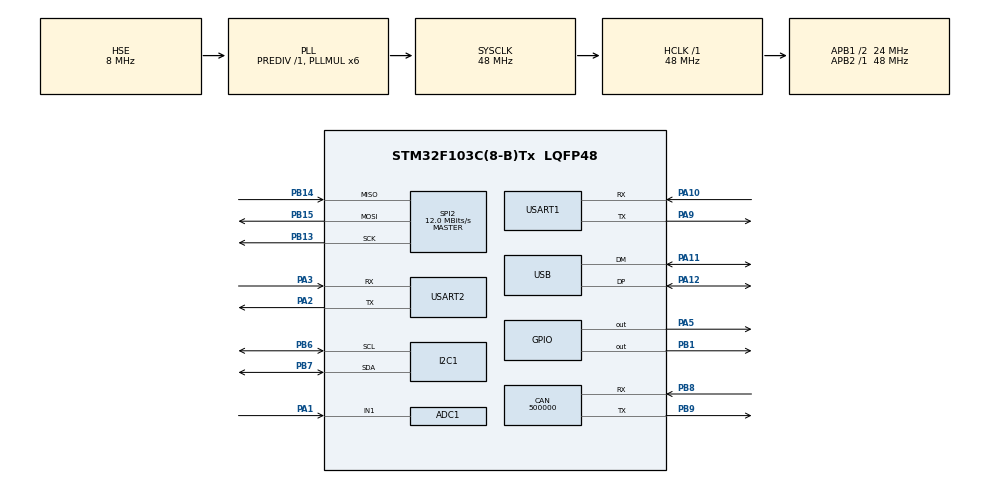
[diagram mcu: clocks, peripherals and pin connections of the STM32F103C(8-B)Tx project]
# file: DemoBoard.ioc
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ADC1.Channel-0\#ChannelRegularConversion=ADC_CHANNEL_1
ADC1.NbrOfConversionFlag=1
ADC1.Rank-0\#ChannelRegularConversion=1
ADC1.SamplingTime-0\#ChannelRegularConversion=ADC_SAMPLETIME_1CYCLE_5
ADC1.master=1
CAN.CalculateBaudRate=500000
CAN.CalculateTimeBit=1999.99
CAN.CalculateTimeQuantum=666.6666666666666
FREERTOS.Tasks01=defaultTask,24,128,StartDefaultTask,Default,NULL,Dynamic,NULL,NULL
Mcu.Family=STM32F1
Mcu.Name=STM32F103C(8-B)Tx
Mcu.Package=LQFP48
NVIC.PriorityGroup=NVIC_PRIORITYGROUP_4
NVIC.USB_LP_CAN1_RX0_IRQn=true\:5\:0\:false\:false\:true\:true\:false\:true
PA1.Signal=ADCx_IN1
PA10.Mode=Asynchronous
PA10.Signal=USART1_RX
PA11.Mode=Device
PA11.Signal=USB_DM
PA12.Mode=Device
PA12.Signal=USB_DP
PA13.Mode=Serial_Wire
PA13.Signal=SYS_JTMS-SWDIO
PA14.Mode=Serial_Wire
PA14.Signal=SYS_JTCK-SWCLK
PA2.Mode=Asynchronous
PA2.Signal=USART2_TX
PA3.Mode=Asynchronous
PA3.Signal=USART2_RX
PA5.Signal=GPIO_Output
PA9.Mode=Asynchronous
PA9.Signal=USART1_TX
PB1.Signal=GPIO_Output
PB13.Mode=Full_Duplex_Master
PB13.Signal=SPI2_SCK
PB14.Mode=Full_Duplex_Master
PB14.Signal=SPI2_MISO
PB15.Mode=Full_Duplex_Master
PB15.Signal=SPI2_MOSI
PB6.Mode=I2C
PB6.Signal=I2C1_SCL
PB7.Mode=I2C
PB7.Signal=I2C1_SDA
PB8.Mode=CAN_Activate
PB8.Signal=CAN_RX
PB9.Mode=CAN_Activate
PB9.Signal=CAN_TX
PD0-OSC_IN.Mode=HSE-External-Oscillator
PD0-OSC_IN.Signal=RCC_OSC_IN
PD1-OSC_OUT.Mode=HSE-External-Oscillator
PD1-OSC_OUT.Signal=RCC_OSC_OUT
ProjectManager.HeapSize=0x200
ProjectManager.StackSize=0x400
ProjectManager.TargetToolchain=STM32CubeIDE
RCC.ADCPresc=RCC_ADCPCLK2_DIV4
RCC.AHBFreq_Value=48000000
RCC.APB1CLKDivider=RCC_HCLK_DIV2
RCC.APB1Freq_Value=24000000
RCC.APB1TimFreq_Value=48000000
RCC.APB2Freq_Value=48000000
RCC.APB2TimFreq_Value=48000000
RCC.HCLKFreq_Value=48000000
RCC.PLLMUL=RCC_PLL_MUL6
RCC.SYSCLKFreq_VALUE=48000000
RCC.SYSCLKSource=RCC_SYSCLKSOURCE_PLLCLK
RCC.USBFreq_Value=48000000
SH.ADCx_IN1.0=ADC1_IN1,IN1
SPI2.CalculateBaudRate=12.0 MBits/s
SPI2.Direction=SPI_DIRECTION_2LINES
SPI2.Mode=SPI_MODE_MASTER
SPI2.VirtualType=VM_MASTER
USART1.VirtualMode=VM_ASYNC
USART2.VirtualMode=VM_ASYNC
USB_DEVICE.CLASS_NAME_FS=CDC
USB_DEVICE.VirtualMode=Cdc
USB_DEVICE.VirtualModeFS=Cdc_FS
VP_FREERTOS_VS_CMSIS_V2.Mode=CMSIS_V2
VP_USB_DEVICE_VS_USB_DEVICE_CDC_FS.Mode=CDC_FS
board=custom

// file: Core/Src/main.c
/* USER CODE BEGIN Header */
/**
  ******************************************************************************
  * @file           : main.c
  * @brief          : Main program body
  ******************************************************************************
  * @attention
  *
  * <h2><center>&copy; Copyright (c) 2021 STMicroelectronics.
  * All rights reserved.</center></h2>
  *
  * This software component is licensed by ST under BSD 3-Clause license,
  * the "License"; You may not use this file except in compliance with the
  * License. You may obtain a copy of the License at:
  *                        opensource.org/licenses/BSD-3-Clause
  *
  ******************************************************************************
  */
/* USER CODE END Header */
#include "main.h"
#include "cmsis_os.h"
#include "usb_device.h"

ADC_HandleTypeDef hadc1;

CAN_HandleTypeDef hcan;

I2C_HandleTypeDef hi2c1;

SPI_HandleTypeDef hspi2;

UART_HandleTypeDef huart1;
UART_HandleTypeDef huart2;

/* Definitions for defaultTask */
osThreadId_t defaultTaskHandle;
const osThreadAttr_t defaultTask_attributes = {
  .name = "defaultTask",
  .priority = (osPriority_t) osPriorityNormal,
  .stack_size = 128 * 4
};

void SystemClock_Config(void);
static void MX_GPIO_Init(void);
static void MX_I2C1_Init(void);
static void MX_USART1_UART_Init(void);
static void MX_USART2_UART_Init(void);
static void MX_ADC1_Init(void);
static void MX_CAN_Init(void);
static void MX_SPI2_Init(void);
void StartDefaultTask(void *argument);

/* USER CODE BEGIN 0 */
#define LED0_Pin        GPIO_PIN_5
#define LED0_GPIO_Port  GPIOA
#define LED_ON          GPIO_PIN_SET
#define LED_OFF          GPIO_PIN_RESET

/* USER CODE END 0 */

int main(void)
{

  /* MCU Configuration--------------------------------------------------------*/

  /* Reset of all peripherals, Initializes the Flash interface and the Systick. */
  HAL_Init();

  /* Configure the system clock */
  SystemClock_Config();

  /* Initialize all configured peripherals */
  MX_GPIO_Init();
  MX_I2C1_Init();
  MX_USART1_UART_Init();
  MX_USART2_UART_Init();
  MX_ADC1_Init();
  MX_CAN_Init();
  MX_SPI2_Init();

  /* Init scheduler */
  osKernelInitialize();

  /* Create the thread(s) */
  /* creation of defaultTask */
  defaultTaskHandle = osThreadNew(StartDefaultTask, NULL, &defaultTask_attributes);

  /* Start scheduler */
  osKernelStart();

  /* We should never get here as control is now taken by the scheduler */
  /* Infinite loop */
  while (1)
  {

  }
}

void SystemClock_Config(void)
{
  RCC_OscInitTypeDef RCC_OscInitStruct = {0};
  RCC_ClkInitTypeDef RCC_ClkInitStruct = {0};
  RCC_PeriphCLKInitTypeDef PeriphClkInit = {0};

  /** Initializes the RCC Oscillators according to the specified parameters
  * in the RCC_OscInitTypeDef structure.
  */
  RCC_OscInitStruct.OscillatorType = RCC_OSCILLATORTYPE_HSE;
  RCC_OscInitStruct.HSEState = RCC_HSE_ON;
  RCC_OscInitStruct.HSEPredivValue = RCC_HSE_PREDIV_DIV1;
  RCC_OscInitStruct.HSIState = RCC_HSI_ON;
  RCC_OscInitStruct.PLL.PLLState = RCC_PLL_ON;
  RCC_OscInitStruct.PLL.PLLSource = RCC_PLLSOURCE_HSE;
  RCC_OscInitStruct.PLL.PLLMUL = RCC_PLL_MUL6;
  if (HAL_RCC_OscConfig(&RCC_OscInitStruct) != HAL_OK)
  {
    Error_Handler();
  }
  /** Initializes the CPU, AHB and APB buses clocks
  */
  RCC_ClkInitStruct.ClockType = RCC_CLOCKTYPE_HCLK|RCC_CLOCKTYPE_SYSCLK
                              |RCC_CLOCKTYPE_PCLK1|RCC_CLOCKTYPE_PCLK2;
  RCC_ClkInitStruct.SYSCLKSource = RCC_SYSCLKSOURCE_PLLCLK;
  RCC_ClkInitStruct.AHBCLKDivider = RCC_SYSCLK_DIV1;
  RCC_ClkInitStruct.APB1CLKDivider = RCC_HCLK_DIV2;
  RCC_ClkInitStruct.APB2CLKDivider = RCC_HCLK_DIV1;

  if (HAL_RCC_ClockConfig(&RCC_ClkInitStruct, FLASH_LATENCY_1) != HAL_OK)
  {
    Error_Handler();
  }
  PeriphClkInit.PeriphClockSelection = RCC_PERIPHCLK_ADC|RCC_PERIPHCLK_USB;
  PeriphClkInit.AdcClockSelection = RCC_ADCPCLK2_DIV4;
  PeriphClkInit.UsbClockSelection = RCC_USBCLKSOURCE_PLL;
  if (HAL_RCCEx_PeriphCLKConfig(&PeriphClkInit) != HAL_OK)
  {
    Error_Handler();
  }
}

static void MX_ADC1_Init(void)
{

  ADC_ChannelConfTypeDef sConfig = {0};

  /** Common config
  */
  hadc1.Instance = ADC1;
  hadc1.Init.ScanConvMode = ADC_SCAN_DISABLE;
  hadc1.Init.ContinuousConvMode = DISABLE;
  hadc1.Init.DiscontinuousConvMode = DISABLE;
  hadc1.Init.ExternalTrigConv = ADC_SOFTWARE_START;
  hadc1.Init.DataAlign = ADC_DATAALIGN_RIGHT;
  hadc1.Init.NbrOfConversion = 1;
  if (HAL_ADC_Init(&hadc1) != HAL_OK)
  {
    Error_Handler();
  }
  /** Configure Regular Channel
  */
  sConfig.Channel = ADC_CHANNEL_1;
  sConfig.Rank = ADC_REGULAR_RANK_1;
  sConfig.SamplingTime = ADC_SAMPLETIME_1CYCLE_5;
  if (HAL_ADC_ConfigChannel(&hadc1, &sConfig) != HAL_OK)
  {
    Error_Handler();
  }

}

static void MX_CAN_Init(void)
{

  hcan.Instance = CAN1;
  hcan.Init.Prescaler = 16;
  hcan.Init.Mode = CAN_MODE_NORMAL;
  hcan.Init.SyncJumpWidth = CAN_SJW_1TQ;
  hcan.Init.TimeSeg1 = CAN_BS1_1TQ;
  hcan.Init.TimeSeg2 = CAN_BS2_1TQ;
  hcan.Init.TimeTriggeredMode = DISABLE;
  hcan.Init.AutoBusOff = DISABLE;
  hcan.Init.AutoWakeUp = DISABLE;
  hcan.Init.AutoRetransmission = DISABLE;
  hcan.Init.ReceiveFifoLocked = DISABLE;
  hcan.Init.TransmitFifoPriority = DISABLE;
  if (HAL_CAN_Init(&hcan) != HAL_OK)
  {
    Error_Handler();
  }

}

static void MX_I2C1_Init(void)
{

  hi2c1.Instance = I2C1;
  hi2c1.Init.ClockSpeed = 100000;
  hi2c1.Init.DutyCycle = I2C_DUTYCYCLE_2;
  hi2c1.Init.OwnAddress1 = 0;
  hi2c1.Init.AddressingMode = I2C_ADDRESSINGMODE_7BIT;
  hi2c1.Init.DualAddressMode = I2C_DUALADDRESS_DISABLE;
  hi2c1.Init.OwnAddress2 = 0;
  hi2c1.Init.GeneralCallMode = I2C_GENERALCALL_DISABLE;
  hi2c1.Init.NoStretchMode = I2C_NOSTRETCH_DISABLE;
  if (HAL_I2C_Init(&hi2c1) != HAL_OK)
  {
    Error_Handler();
  }

}

static void MX_SPI2_Init(void)
{

  /* SPI2 parameter configuration*/
  hspi2.Instance = SPI2;
  hspi2.Init.Mode = SPI_MODE_MASTER;
  hspi2.Init.Direction = SPI_DIRECTION_2LINES;
  hspi2.Init.DataSize = SPI_DATASIZE_8BIT;
  hspi2.Init.CLKPolarity = SPI_POLARITY_LOW;
  hspi2.Init.CLKPhase = SPI_PHASE_1EDGE;
  hspi2.Init.NSS = SPI_NSS_SOFT;
  hspi2.Init.BaudRatePrescaler = SPI_BAUDRATEPRESCALER_2;
  hspi2.Init.FirstBit = SPI_FIRSTBIT_MSB;
  hspi2.Init.TIMode = SPI_TIMODE_DISABLE;
  hspi2.Init.CRCCalculation = SPI_CRCCALCULATION_DISABLE;
  hspi2.Init.CRCPolynomial = 10;
  if (HAL_SPI_Init(&hspi2) != HAL_OK)
  {
    Error_Handler();
  }

}

static void MX_USART1_UART_Init(void)
{

  huart1.Instance = USART1;
  huart1.Init.BaudRate = 115200;
  huart1.Init.WordLength = UART_WORDLENGTH_8B;
  huart1.Init.StopBits = UART_STOPBITS_1;
  huart1.Init.Parity = UART_PARITY_NONE;
  huart1.Init.Mode = UART_MODE_TX_RX;
  huart1.Init.HwFlowCtl = UART_HWCONTROL_NONE;
  huart1.Init.OverSampling = UART_OVERSAMPLING_16;
  if (HAL_UART_Init(&huart1) != HAL_OK)
  {
    Error_Handler();
  }

}

static void MX_USART2_UART_Init(void)
{

  huart2.Instance = USART2;
  huart2.Init.BaudRate = 115200;
  huart2.Init.WordLength = UART_WORDLENGTH_8B;
  huart2.Init.StopBits = UART_STOPBITS_1;
  huart2.Init.Parity = UART_PARITY_NONE;
  huart2.Init.Mode = UART_MODE_TX_RX;
  huart2.Init.HwFlowCtl = UART_HWCONTROL_NONE;
  huart2.Init.OverSampling = UART_OVERSAMPLING_16;
  if (HAL_UART_Init(&huart2) != HAL_OK)
  {
    Error_Handler();
  }

}

static void MX_GPIO_Init(void)
{
  GPIO_InitTypeDef GPIO_InitStruct = {0};

  /* GPIO Ports Clock Enable */
  __HAL_RCC_GPIOD_CLK_ENABLE();
  __HAL_RCC_GPIOA_CLK_ENABLE();
  __HAL_RCC_GPIOB_CLK_ENABLE();

  /*Configure GPIO pin Output Level */
  HAL_GPIO_WritePin(GPIOA, GPIO_PIN_5, GPIO_PIN_RESET);

  /*Configure GPIO pin Output Level */
  HAL_GPIO_WritePin(GPIOB, GPIO_PIN_1, GPIO_PIN_RESET);

  /*Configure GPIO pin : PA5 */
  GPIO_InitStruct.Pin = GPIO_PIN_5;
  GPIO_InitStruct.Mode = GPIO_MODE_OUTPUT_PP;
  GPIO_InitStruct.Pull = GPIO_NOPULL;
  GPIO_InitStruct.Speed = GPIO_SPEED_FREQ_LOW;
  HAL_GPIO_Init(GPIOA, &GPIO_InitStruct);

  /*Configure GPIO pin : PB1 */
  GPIO_InitStruct.Pin = GPIO_PIN_1;
  GPIO_InitStruct.Mode = GPIO_MODE_OUTPUT_PP;
  GPIO_InitStruct.Pull = GPIO_NOPULL;
  GPIO_InitStruct.Speed = GPIO_SPEED_FREQ_LOW;
  HAL_GPIO_Init(GPIOB, &GPIO_InitStruct);

}

void StartDefaultTask(void *argument)
{
  /* init code for USB_DEVICE */
  MX_USB_DEVICE_Init();
  for(;;)
  {
    osDelay(1);
  }
}

void Error_Handler(void)
{
  __disable_irq();
  while (1)
  {
  }
}

/************************ (C) COPYRIGHT STMicroelectronics *****END OF FILE****/
